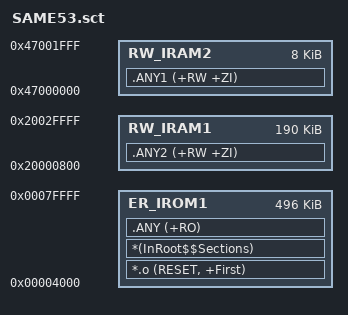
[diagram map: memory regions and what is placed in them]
; *************************************************************
; *** Scatter-Loading Description File generated by uVision ***
; *************************************************************

LR_IROM1 0x00004000 0x0007C000  {    ; load region size_region
  ER_IROM1 0x00004000 0x0007C000  {  ; load address = execution address
   *.o (RESET, +First)
   *(InRoot$$Sections)
   .ANY (+RO)
  }

  RW_IRAM1 0x20000800 0x0002F800 {  ; RW data
   ;*(SEGGER_RTT_RW, +First)
   .ANY2 (+RW +ZI)
  }

  RW_IRAM2 0x47000000 0x00002000 {  ; RW data
   .ANY1 (+RW +ZI)
  }
}

